# MMCSD8_MMC_CTLCFG_0FA00000h register map
Vendor: Texas Instruments
Registers are 16-bit, read-write, reset 0x0 unless marked. A register's access mark holds for its fields unless they carry their own. Offsets are as the file gives them; [hi:lo] are bit positions; lines under a group give offsets from that group.

## mmc_ctlcfg (part 4 of 4)
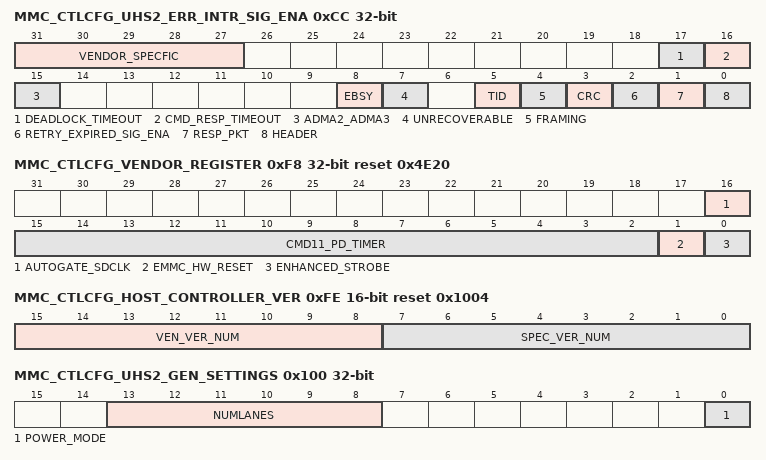
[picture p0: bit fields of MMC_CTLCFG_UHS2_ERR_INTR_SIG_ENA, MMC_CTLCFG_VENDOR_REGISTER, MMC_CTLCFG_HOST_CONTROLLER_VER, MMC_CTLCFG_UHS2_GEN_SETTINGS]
0xCC MMC_CTLCFG_UHS2_ERR_INTR_SIG_ENA 32-bit — This register is used to generate UHS-II Interrupt signals
  [31:27] VENDOR_SPECFIC — Setting of a bit to 1 in this field enables generating interrupt signal when corre-spondent bit of Vendor Specific Error is set in the UHS-II Error Interrupt Status Register. 0h - Interrupt Signal is Disabled 1h - Interrupt Signal is Enabled Reset Source: vbus_amod_g_rst_n
  [17] DEADLOCK_TIMEOUT — Setting this bit to 1 enables generating interrupt signal when Timeout for Dead lock bit is set in the UHS-II Error InterruptStatus Register. 0 Interrupt Signal is Disabled1 Interrupt Signal is Enabled
  [16] CMD_RESP_TIMEOUT — Setting this bit to 1 enables generating interrupt signal when Timeout for CMD_RES bit is set in the UHS-II Error InterruptStatus Register. 0 Interrupt Signal is Disabled1 Interrupt Signal is Enabled
  [15] ADMA2_ADMA3 — Setting this bit to 1 enables generating interrupt signal when ADMA2/3 Error bit is set in the UHS-II Error InterruptStatus Register. 0 Interrupt Signal is Disabled1 Interrupt Signal is Enabled
  [8] EBSY — Setting this bit to 1 enables generating interrupt signal when EBSY Error bit is set in the UHS-II Error InterruptStatus Register. 0 Interrupt Signal is Disabled1 Interrupt Signal is Enabled
  [7] UNRECOVERABLE — Setting this bit to 1 enables generating interrupt signal when Unrecoverable Error bit is set in the UHS-II Error InterruptStatus Register. 0 Interrupt Signal is Disabled1 Interrupt Signal is Enabled
  [5] TID — Setting this bit to 1 enables generating interrupt signal when TID Error bit is set in the UHS-II Error InterruptStatus Register. 0 Interrupt Signal is Disabled1 Interrupt Signal is Enabled
  [4] FRAMING — Setting this bit to 1 enables generating interrupt signal when Framing Error bit is set in the UHS-II Error InterruptStatus Register. 0 Interrupt Signal is Disabled1 Interrupt Signal is Enabled
  [3] CRC — Setting this bit to 1 enables generating interrupt signal when CRC Error bit is set in the UHS-II Error InterruptStatus Register. 0 Interrupt Signal is Disabled1 Interrupt Signal is Enabled
  [2] RETRY_EXPIRED_SIG_ENA — Setting this bit to 1 enables generating interrupt signal when Retry Expired bit is set in the UHS-II Error InterruptStatus Register. 0 Interrupt Signal is Disabled1 Interrupt Signal is Enabled
  [1] RESP_PKT — Setting this bit to 1 enables generating interrupt signal when RES Packet Error bit is set in the UHS-II Error InterruptStatus Register. 0 Interrupt Signal is Disabled1 Interrupt Signal is Enabled
  [0] HEADER — Setting this bit to 1 enables generating interrupt signal when Header Error bit is set in the UHS-II Error Interrupt Status Register. 0 Interrupt Signal is Disabled1 Interrupt Signal is Enabled
0xE0 MMC_CTLCFG_UHS2_SETTINGS_PTR ro reset 0x100 — This register is pointer for UHS-II settings.
  [15:0] UHS2_SETTINGS_PTR — Pointer for UHS-II Settings Register Reset Source: vbus_amod_g_rst_n
0xE2 MMC_CTLCFG_UHS2_CAPABILITIES_PTR ro reset 0x110 — This register is pointer for UHS-II Capabilities Register.
  [15:0] UHS2_CAPABILITIES_PTR — Pointer for UHS-II Capabilities Register Reset Source: vbus_amod_g_rst_n
0xE4 MMC_CTLCFG_UHS2_TEST_PTR ro reset 0x120 — This register is pointer for UHS-II Test Register.
  [15:0] UHS2_TEST_PTR — Pointer for UHS-II Test Register Reset Source: vbus_amod_g_rst_n
0xE6 MMC_CTLCFG_SHARED_BUS_CTRL_PTR ro reset 0x130 — This register is pointer for UHS-II Shared Bus Control Register.
  [15:0] SHARED_BUS_CTRL_PTR — Pointer for Shared Bus Control Register Reset Source: vbus_amod_g_rst_n
0xE8 MMC_CTLCFG_VENDOR_SPECFIC_PTR ro reset 0x140 — This register is pointer for UHS-II Vendor Specific Pointer Register.
  [15:0] VENDOR_SPECFIC_PTR — Pointer for Vendor Specific Area Reset Source: vbus_amod_g_rst_n
0xF4 MMC_CTLCFG_BOOT_TIMEOUT_CONTROL 32-bit — This is used to program the boot timeout value counter
  [31:0] DATA_TIMEOUT_CNT — This value determines the interval by which DAT line time-outs are detected during boot operation for eMMC4.4 card.The value is in number of sd clock. Reset Source: vbus_amod_g_rst_n
0xF8 MMC_CTLCFG_VENDOR_REGISTER 32-bit reset 0x4E20 — Vendor register added for autogate sdclk, cmd11 power down timer, enhancedstrobe and eMMC hardware reset
  [16] AUTOGATE_SDCLK — If this bit is set, SD CLK will be gated automatically when there is no transfer. This is applicable only for Embedded Device 0 Autogating of sdclk is Disabled1 Autogating of sdclk is Enabled
  [15:2] CMD11_PD_TIMER — cmd11 power-down timer value Reset Source: vbus_amod_g_rst_n
  [1] EMMC_HW_RESET — Hardware reset signal is generared for eMMC card when this bit is set 0 Deassert the hardware reset pin1 Drives the hardware reset pin as ZERO (Active LOW to eMMC card)
  [0] ENHANCED_STROBE — This bit enables the enhanced strobe logic of the Host Controller 0 Enhanced strobe is Disabled1 Enhanced strobe is Enabled
0xFC MMC_CTLCFG_SLOT_INT_STS ro — This register is used to read the interrupt signal for each slot.
  [7:0] INTR_SIG — These status bits indicate the logical OR of Interrupt signal and Wakeup signal for each slot. Reset Source: vbus_amod_g_rst_n
0xFE MMC_CTLCFG_HOST_CONTROLLER_VER ro reset 0x1004 — This register is used to read the vendor version number and specification version number
  [15:8] VEN_VER_NUM — The Vendor Version Number is set to 0x10 [1.0] Reset Source: vbus_amod_g_rst_n
  [7:0] SPEC_VER_NUM — This status indicates the Host Controller Spec. Version. The upper and lower 4-bits indicate the version. 00h - SD Host Controller Specification Version 1.00 01h - SD Host Controller Specification Version 2.00 Including the feature of the ADMA and Test Register 02h - SD Host Controller Specification Version 3.00 03h - SD Host Controller Specification Version 4.00 04h - SD Host Controller Specification Version 4.10 'others' Reserved 0 SD Host Controller Specifiation Version 1.001 SD Host Controller Specifiation Version 2.002 SD Host Controller Specifiation Version 3.003 SD Host Controller Specifiation Version 4.004 SD Host Controller Specifiation Version 4.10
0x100 MMC_CTLCFG_UHS2_GEN_SETTINGS 32-bit — Start Address of General settings is pointed by Pointer for UHS-II Setting Register.
  [13:8] NUMLANES — The lane configuration of a Host System is set to this field depends on the capability among Host Controller and connected devices. 2 Lanes FD mode is mandatory and the others modes are optional. 0000b - 2 Lanes FD or 2L-HD 0001b - Not Used 0010b - 3 Lanes 2D1U-FD [Embedded] 0011b - 3 Lanes 1D2U-FD [Embedded] 0100b - 4 Lanes 2D2U-FD [Embedded] others - Reserved Reset Source: vbus_amod_g_rst_n
  [0] POWER_MODE — This field determines either Fast mode or Low Power mode.Host and all devices connected to the host shall be set to the same mode. 0 Fast mode1 Low power mode
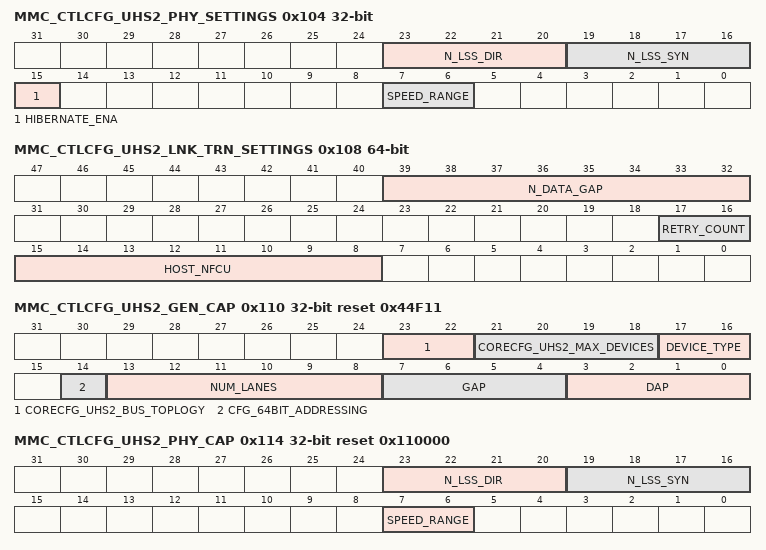
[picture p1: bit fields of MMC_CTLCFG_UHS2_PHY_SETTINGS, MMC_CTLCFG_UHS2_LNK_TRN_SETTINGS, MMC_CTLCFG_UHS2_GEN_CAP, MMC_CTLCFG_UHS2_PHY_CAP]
0x104 MMC_CTLCFG_UHS2_PHY_SETTINGS 32-bit — Start Address of PHY settings is pointed by Pointer for UHS-II Setting Register.
  [23:20] N_LSS_DIR — The largest value of N_LSS_DIR capabilities among the Host Controller and Connected Devices is set to this field. 0h - 8 x16 LSS 1h - 8 x 1 LSS 2h - 8 x 2 LSS 3h - 8 x 3 LSS ...... ...... Fh - 8 x 15 LSS Reset Source: vbus_amod_g_rst_n
  [19:16] N_LSS_SYN — The largest value of N_LSS_SYN capabilities among the Host Controller and Connected Devices is set to this field. 0h - 4 x16 LSS 1h - 4 x 1 LSS 2h - 4 x 2 LSS 3h - 4 x 3 LSS ...... ...... Fh - 4 x 15 LSS Reset Source: vbus_amod_g_rst_n
  [15] HIBERNATE_ENA — After checking card capability of Hibernate mode, if all devices support Hibernate mode, this bit may be set. This bit determines whether Host remains in Dormant state or goes to Hibernate state. In Hibernate mode, VDD1 Power may be off. 0 Hibernate Disabled1 Hibernate Enabled
  [7:6] SPEED_RANGE — PLL multiplier is selected by this field.Change of PLL Multiplier is not effective immediately and is applied from exiting Dormant State. '00' Range A [Default] '01' Range B '10' Reserved '11' Reserved 0 Range A (Default)1 Range B2 Reserved3 Reserved
0x108 MMC_CTLCFG_UHS2_LNK_TRN_SETTINGS 64-bit — Start Address of LINK/TRAN settings is pointed by Pointer for UHS-II Setting Register.
  [39:32] N_DATA_GAP — The largest value of N_DATA_GAP capabilities among the Host Controller and Connected Devices is set to this field. 00h - No Gap 01h - 1 LSS 02h - 2 LSS 03h - 3 LSS ...... ...... FFh - 255 LSS 0 No Gap1 1 LSS2 2 LSS3 3 LSS255 255 LSS
  [17:16] RETRY_COUNT — Data Burst retry count is set to this field. '00' Retry Disabled '01' 1 time '10' 2 times '11' 3 times 0 Retry Disabled1 Retry 1time2 Retry 2times3 Retry 3times
  [15:8] HOST_NFCU — Host Driver sets the number of blocks in Data Burst [Flow Control] to this field.The value shall be smaller than or equal to N_FCU capabilities among the Host Controller and connected card and devices. Setting 1 to 4 blocks is recommended considering buffer size. 00h - 256 Blocks 01h - 1 Block 02h - 2 Blocks 03h - 3 Blocks ...... ...... FFh - 255 Blocks 0 256 Blocks1 1 Block2 2 Blocks3 3 Blocks255 255 Blocks
0x110 MMC_CTLCFG_UHS2_GEN_CAP 32-bit ro reset 0x44F11 — Start Address of General Capabilities is pointed by Pointer for UHS-II Host Capabilities Register.
  [23:22] CORECFG_UHS2_BUS_TOPLOGY — This field indicates one of bus topologies configured by a Host system. '00' P2P Connection '01' Ring Connection '10' HUB Connection '11' HUB is connected in Ring 0 P2P Connection1 Ring Connection2 HUB Connection3 HUB is connected in Ring
  [21:18] CORECFG_UHS2_MAX_DEVICES — This field indicates the maximum number of devices supported by the Host Controller. 0h - Not used 1h - 1 Devices 2h - 2 Devices ..... ....... Fh - 15 Devices 0 Not used1 1 Device2 2 Devices15 15 Devices
  [17:16] DEVICE_TYPE — This field indicates device type configured by a Host system. '00' Removable Card[P2P] '01' Embedded Devices '10' Embedded Devices+Removable Card '11' Reserved Reset Source: vbus_amod_g_rst_n
  [14] CFG_64BIT_ADDRESSING — This field indicates support of 64-bit addressing by the Host Controller. '0' 32-bit Addressing is supported '1' 32-bit and 64-bit Addressing is supported Reset Source: vbus_amod_g_rst_n
  [13:8] NUM_LANES — This field indicates support of lanes by the Host Controller.0 mean not supported and 1 means supported. D08 - 2L-HD D09 - 2D1U-FD D10 - 1D2U-FD D11 - 2D2U-FD D12 - Reserved D13 - Reserved Reset Source: vbus_amod_g_rst_n
  [7:4] GAP — This field indicates the maximum capability of host power supply for a group configured by a Host system.This field is used to set the argument of DEVICE_INIT CCMD 0h -Not used 1h - 360 mW 2h - 720 mW ..... ....... Fh - 360x15 mW Reset Source: vbus_amod_g_rst_n
  [3:0] DAP — This field indicates the maximum capability of host power supply for a device configured by a Host system.This field is used to set the argument of DEVICE_INIT CCMD 0h -360 mW [Default] 1h - 360 mW 2h - 720 mW ..... ....... Fh - 360 x15 mW Reset Source: vbus_amod_g_rst_n
0x114 MMC_CTLCFG_UHS2_PHY_CAP 32-bit ro reset 0x110000 — Start Address of PHY Capabilities is pointed by Pointer for UHS-II Host Capabilities Register.
  [23:20] N_LSS_DIR — This field indicates the minimum N_LSS_DIR required by the Host Controller. 0h - 4 x16 LSS 1h - 4 x 1 LSS 2h - 4 x 2 LSS 3h - 4 x 3 LSS ...... ...... Fh - 4 x 15 LSS Reset Source: vbus_amod_g_rst_n
  [19:16] N_LSS_SYN — This field indicates the minimum N_LSS_SYN required by the Host Controller. 0h - 4 x16 LSS 1h - 4 x 1 LSS 2h - 4 x 2 LSS 3h - 4 x 3 LSS ...... ...... Fh - 4 x 15 LSS Reset Source: vbus_amod_g_rst_n
  [7:6] SPEED_RANGE — This field indicates supported Speed Range by the Host Controller '00' Range A [Default] '01' Range A and Range B '10' Reserved '11' Reserved 0 Range A (Default)1 Range A and Range B2 Reserved3 Reserved
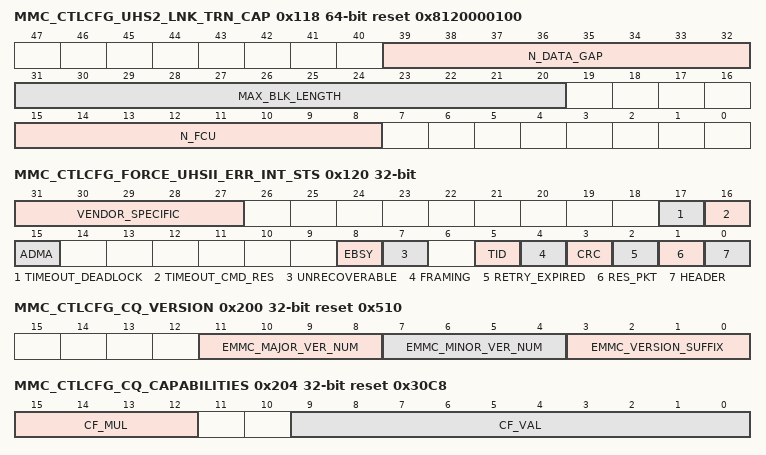
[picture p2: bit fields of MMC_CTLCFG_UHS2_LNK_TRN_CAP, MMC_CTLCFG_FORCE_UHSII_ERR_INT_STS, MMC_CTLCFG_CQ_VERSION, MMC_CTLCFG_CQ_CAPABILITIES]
0x118 MMC_CTLCFG_UHS2_LNK_TRN_CAP 64-bit ro reset 0x8120000100 — Start Address of LINK/TRAN settings is pointed by Pointer for UHS-II Capabilities Register.
  [39:32] N_DATA_GAP — This field indicates the minimum number of data gap[DIDL] supported by the Host Controller. 00h - No Gap 01h - 1 LSS 02h - 2 LSS 03h - 3 LSS ...... ...... FFh - 255 LSS 0 No Gap1 1 LSS2 2 LSS3 3 LSS255 255 LSS
  [31:20] MAX_BLK_LENGTH — This field indicates maximum block length by the Host Controller. 000h - Not Used 001h - 1 byte 002h - 2 bytes ...... ...... 200h - 512 bytes ...... ...... 800h - 2048 bytes 801h-FFFh -Not Used Reset Source: vbus_amod_g_rst_n
  [15:8] N_FCU — This field indicates maximum the number of blocks in a Flow Control unit by the Host Controller.This value is determined by supported buffer size. 00h - 256 Blocks 01h - 1 Block 02h - 2 Block 03h - 3 Block ....... FFh - 255 Blocks 0 256 Blocks1 1 Block2 2 Blocks3 3 Blocks255 255 Blocks
0x120 MMC_CTLCFG_FORCE_UHSII_ERR_INT_STS 32-bit wo — This register is not physically implemented, rather it is an address where UHS-II Error Interrupt Status register can be written.
  [31:27] VENDOR_SPECIFIC — Force Event for Vendor Specific Error 0h - Not Affected 1h - Vendor Specific Error Status is set Reset Source: vbus_amod_g_rst_n
  [17] TIMEOUT_DEADLOCK — Setting this bit forces the Host Controller to set Timeout for Deadlock in the UHS-II Error Interrupt Status register. 0 No Interrupt1 Timeout for Deadlock Error status is set
  [16] TIMEOUT_CMD_RES — Setting this bit forces the Host Controller to set Timeout for CMD_RES in the UHS-II Error Interrupt Status register. 0 No Interrupt1 Timout for CMD_RES Status is set
  [15] ADMA — Setting this bit forces the Host Controller to set ADMA Error in the UHS-II Error Interrupt Status register. 0 No Interrupt1 ADMA error status is set
  [8] EBSY — Setting this bit forces the Host Controller to set EBSY Error in the UHS-II Error Interrupt Status register. 0 No Interrupt1 EBSY error status is set
  [7] UNRECOVERABLE — Setting this bit forces the Host Controller to set Unrecover-able Error in the UHS-II Error Interrupt Status register. 0 No Interrupt1 Unrecoverable error status is set
  [5] TID — Setting this bit forces the Host Controller to set TID Error in the UHS-II Error Interrupt Status register. 0 No Interrupt1 TID error status is set
  [4] FRAMING — Setting this bit forces the Host Controller to set Framing Error in the UHS-II Error Interrupt Status register. 0 No Interrupt1 Framing error status is set
  [3] CRC — Setting this bit forces the Host Controller to set CRC Error in the UHS-II Error Interrupt Status register. 0 No Interrupt1 CRC error status is set
  [2] RETRY_EXPIRED — Setting this bit forces the Host Controller to set Retry Expired in the UHS-II Error Interrupt Status register. 0 No Interrupt1 Retry expired error status is set
  [1] RES_PKT — Setting this bit forces the Host Controller to set RES Packet Error in the UHS-II Error Interrupt Status register. 0 No Interrupt1 RES packet error status is set
  [0] HEADER — Setting this bit forces the Host Controller to set Header Error in the UHS-II Error Interrupt Status register. 0 No Interrupt1 Header error status is set
0x200 MMC_CTLCFG_CQ_VERSION 32-bit ro reset 0x510 — This register provides information about the version of the eMMC CQ standard which is 285 implemented by the CQE, in BCD format. The current version is rev 5.1 The following table describes the CQBASE+00h: CQVReservedER Command Queueing Version.
  [11:8] EMMC_MAJOR_VER_NUM — eMMC Major Version Number [digit left of decimal point],in BCD format Reset Source: vbus_amod_g_rst_n
  [7:4] EMMC_MINOR_VER_NUM — eMMC Minor Version Number [digit right of decimal point], in BCD format Reset Source: vbus_amod_g_rst_n
  [3:0] EMMC_VERSION_SUFFIX — eMMC Version Suffix [2nd digit right of decimal point], in BCD format Reset Source: vbus_amod_g_rst_n
0x204 MMC_CTLCFG_CQ_CAPABILITIES 32-bit ro reset 0x30C8 — This register is reserved for capability indication.
  [15:12] CF_MUL — Internal Timer Clock Frequency Multiplier [ITCFMUL] ITCFMUL and ITCFVAL indicate the frequency of the clock used for interrupt coalescing timer and for deter-mining the SQS polling period. See ITCFVAL definition for details. Field Value Description: 0h = 0.001 MHz 1h = 0.01 MHz 2h = 0.1 MHz 3h = 1 MHz 4h = 10 MHz Other values are reserved 3 1 MHz4 10 MHz
  [9:0] CF_VAL — Internal Timer Clock Frequency Value [ITCFVAL] TCFMUL and ITCFVAL indicate the frequency of the clock used for interrupt coalescing timer and for deter-mining the polling period when using periodic SEND_QUEUE_ STATUS [CMD13] polling. The clock frequency is calculated as ITCFVAL*ITCFMUL. For example, to encode 19.2 MHz ITCFVAL shall be C0h [= 192 decimal] and ITCFMUL shall be 2h [0.1 MHz 192 * 0.1 MHz 19.2 MHz] Reset Source: vbus_amod_g_rst_n
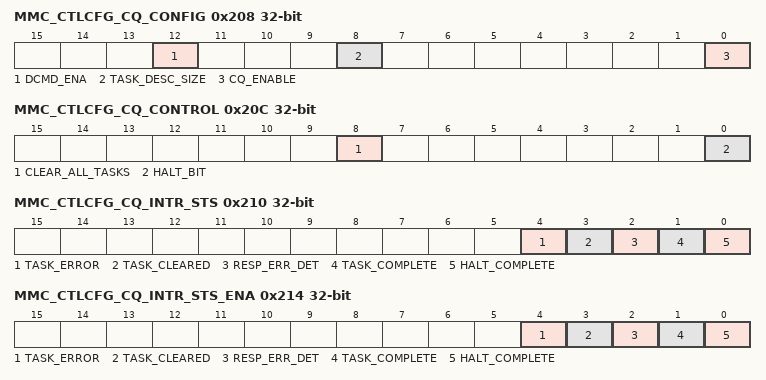
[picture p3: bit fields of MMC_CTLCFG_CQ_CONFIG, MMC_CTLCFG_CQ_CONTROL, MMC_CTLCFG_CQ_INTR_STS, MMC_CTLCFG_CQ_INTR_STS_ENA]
0x208 MMC_CTLCFG_CQ_CONFIG 32-bit — This register controls CQE behavior affecting the general operation of command queueing 290 module or operation of multiple tasks in the same time.
  [12] DCMD_ENA — Direct Command [DCMD] Enable This bit indicates to the hardware whether the Task Descriptor in slot #31 of the TDL is a Data Transfer Task Descriptor, or a Direct Command Task Descriptor. CQE uses this bit when a task is issued in slot #31, to determine how to decode the Task Descriptor. Bit Value Description 1 = Task descriptor in slot #31 is a DCMD Task Descrip-tor 0 = Task descriptor in slot #31 is a Data Transfer Task Descriptor 0 Task descriptor in slot #31 is a Data Transfer Task Descriptor1 Task descriptor in slot #31 is a DCMD Task Descriptor
  [8] TASK_DESC_SIZE — Task Descriptor Size This bit indicates whether the task descriptor size is 128 bits or 64 bits as detailed in Data Structures section. This bit can only be configured when Command Queueing Enable bit is 0 [command queueing is disabled] Bit Value Description 1 = Task descriptor size is 128 bits 0 = Task descriptor size is 64 bits 0 Task descriptor size is 64 bits1 Task descriptor size is 128 bits
  [0] CQ_ENABLE — Command Queueing Enable Software shall write 1 this bit when in order to enable command queueing mode [i.e. enable CQE]. When this bit is 0, CQE is disabled and software controls the eMMC bus using the legacy eMMC host controller. Before software writes 1 to this bit, software shall verify that the eMMC host controller is in idle state and there are no commands or data transfers ongoing. When software wants to exit command queueing mode,it shall clear all previous tasks if such exist before setting this bit to 0. 0 Command Queueing mode is Disabled1 Command Queueing mode is Enabled
0x20C MMC_CTLCFG_CQ_CONTROL 32-bit — This register controls CQE behavior affecting the general operation of command queueing 293 module or operation of multiple tasks in the same time.
  [8] CLEAR_ALL_TASKS — Clear All Tasks Software shall write 1 this bit when it wants to clear all the tasks sent to the device. This bit can only be written when CQE is in halt state [i.e.Halt bit is 1]. When software writes 1, the value of the register is updated to 1, and CQE shall reset CQTDBR register and all other context information for all unfinished tasks. Then CQE will clear this bit.Software should poll on this bit until it is set to back 0 and may then resume normal operation, by clearing the Halt bit. CQE does not communicate to the device that the tasks were cleared. It is softwares responsibility to order the device to discard the tasks in its queue using CMDQ_TASK_MGMT command. Writing 0 to this register shall have no effect. Reset Source: vbus_amod_g_rst_n
  [0] HALT_BIT — Halt Host software shall write 1 to the bit when it wants to acquire software control over the eMMC bus and disable CQE from issuing commands on the bus. For example, issuing a Discard Task command [CMDQ_TASK_MGMT] When software writes 1, CQE shall complete the ongo-ing task if such a task is in progress. Once the task is completed and CQE is in idle state,CQE shall not issue new commands and shall indicate so to software by setting this bit to 1. Software may poll on this bit until it is set to 1, and may only then send commands on the eMMC bus. In order to exit halt state [i.e. resume CQE activity], soft-ware shall clear this bit [write 0]. Writing 0 when thevalue is already 0 shall have no effect. Reset Source: vbus_amod_g_rst_n
0x210 MMC_CTLCFG_CQ_INTR_STS 32-bit access not given — This register indicates pending interrupts that require service. Each bit in this registers is asserted 296 in response a specific event, only if the respective bit is set in CQ ISTE register.
  [4] TASK_ERROR — Task Error Interrupt [TERR] This bit is asserted when task error is detected due to invalid task descriptor 0 No Interrupt1 Task Error interrupt is generated (access R/W1TC)
  [3] TASK_CLEARED — Task Cleared [TCL] This status bit is asserted [if CQISTE.TCL=1] when a task clear operation is completed by CQE. The com-pleted task clear operation is either an individual task clear [CQTCLR] or clearing of all tasks [CQCTL]. 0 No Interrupt1 Task clear interrupt is generated (access R/W1TC)
  [2] RESP_ERR_DET — Response Error Detected Interrupt [RED] This status bit is asserted [if CQISTE.RED=1] when a response is received with an error bit set in the device status field. The contents of the device status field are listed in Section 6.13.Software uses CQRMEM register to configure which device status bit fields may trigger an interrupt, and which are masked. Reset Source: vbus_amod_g_rst_n (access R/W1TC)
  [1] TASK_COMPLETE — Task Complete Interrupt [TCC] This status bit is asserted [if CQISTE.TCC=1] when atleast one of the following two conditions are met: [1] A task is completed and the INT bit is set in its Task Descriptor [2] Interrupt caused by Interrupt Coalescing logic [see Section C.4.9] 0 No Interrupt1 Task complete interrupt is generated (access R/W1TC)
  [0] HALT_COMPLETE — Halt Complete Interrupt [HAC] This status bit is asserted [if CQISTE.HAC=1] when halt bit in CQCTL register transitions from 0 to 1 indicating that host controller has completed its current ongoing task and has entered halt state. 0 No Interrupt1 Halt complete interrupt is generated (access R/W1TC)
0x214 MMC_CTLCFG_CQ_INTR_STS_ENA 32-bit — This register enables and disables the reporting of the corresponding interrupt to host soft-ware in 299 CQIS register. When a bit is set ( 1 ) and the corresponding interrupt c -ondition is active, then the 300 bit is CQIS is asserted. Interrupt sources that are disabled ( 0 ) are not indicated in the CQIS 301 register. This register is bit-index matched to CQIS register.
  [4] TASK_ERROR — Task Error Interrupt Status Enable 1 = CQIS.TERR will be set when its interrupt condition is active 0 = CQIS.TERR is disabled 01
  [3] TASK_CLEARED — Task Cleared Status Enable [TCL] 1 = CQIS.TCL will be set when its interrupt condition is active 0 = CQIS.TCL is disabled 01
  [2] RESP_ERR_DET — Response Error Detected Status Enable [RED] 1 = CQIS.RED will be set when its interrupt condition is active 0 = CQIS.RED is disabled 01
  [1] TASK_COMPLETE — Task Complete Status Enable [TCC] 1 = CQIS.TCC will be set when its interrupt condition is active 0 = CQIS.TCC is disabled 01
  [0] HALT_COMPLETE — Halt Complete Status Enable [HAC] 1 = CQIS.HAC will be set when its interrupt condition is active 0 = CQIS.HAC is disabled 01
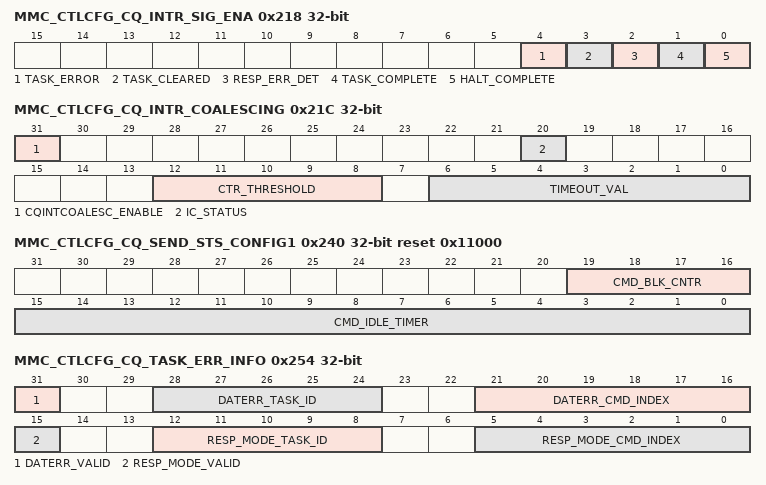
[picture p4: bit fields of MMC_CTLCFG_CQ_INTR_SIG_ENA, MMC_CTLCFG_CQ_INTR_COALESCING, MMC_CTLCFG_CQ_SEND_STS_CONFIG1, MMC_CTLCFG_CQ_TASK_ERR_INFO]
0x218 MMC_CTLCFG_CQ_INTR_SIG_ENA 32-bit — This register enables and disables the generation of interrupts to host software. When a bit is set 304 ( 1 ) and the corresponding bit in CQIS is set, then an interrupt is gene -rated. Interrupt sources 305 that are disabled ( 0 ) are still indicated in the CQIS register. This register is bit-index matched 306 to CQIS register.
  [4] TASK_ERROR — Task Error Interrupt Signal Enable [TERR] When set and CQIS.TERR is asserted, the CQE shall generate an interrupt 01
  [3] TASK_CLEARED — Task Cleared Signal Enable [TCL] When set and CQIS.TCL is asserted, the CQE shall generate an interrupt 01
  [2] RESP_ERR_DET — Response Error Detected Signal Enable [TCC] When set and CQIS.RED is asserted, the CQE shall generate an interrupt 01
  [1] TASK_COMPLETE — Task Complete Signal Enable [TCC] When set and CQIS.TCC is asserted, the CQE shall generate an interrupt 01
  [0] HALT_COMPLETE — Halt Complete Signal Enable [HAC] When set and CQIS.HAC is asserted, the CQE shall generate an interrupt 01
0x21C MMC_CTLCFG_CQ_INTR_COALESCING 32-bit access per field — This register controls the interrupt coalescing feature.
  [31] CQINTCOALESC_ENABLE rw — When set to 0 by software, command responses are neither counted nor timed. Interrupts are still triggered by completion of tasks with INT=1 in the Task Descriptor. When set to 1, the interrupt coalescing mechanism is enabled and coalesced interrupts are generated. Reset Source: vbus_amod_g_rst_n
  [20] IC_STATUS ro — This bit indicates to software whether any tasks [with INT=0] have completed and counted towards interrupt coalescing [i.e., ICSB is set if and only if IC counter > 0]. Bit Value Description 1 = At least one task completion has been counted [IC counter >0] 0 = No task completions have occurred since last counter reset [IC counter =0] Reset Source: vbus_amod_g_rst_n
  [12:8] CTR_THRESHOLD rw — Interrupt Coalescing Counter Threshold [ICCTH]: Software uses this field to configure the number of task completions [only tasks with INT=0 in the Task Descriptor] which are required in order to generate an interrupt. Counter Operation: As data transfer tasks with INT=0 complete, they are counted by CQE. The counter is reset by software during the interrupt service routine. The counter stops counting when it reaches the value configured in ICCTH. The maximum allowed value is 31 NOTE : When ICCTH is 0, task completions are not counted, and counting-based interrupts are not generated.In order to write to this field, the ICCTHWEN bit must be set at the same write operation. Reset Source: vbus_amod_g_rst_n
  [6:0] TIMEOUT_VAL rw — Interrupt Coalescing Timeout Value [ICTOVAL]: Software uses this field to configure the maximum time allowed between the completion of a task on the bus and the generation of an interrupt. Timer Operation: The timer is reset by software during the interrupt service routine. It starts running when a data transfer task with INT=0 is completed, after the timer was reset. When the timer reaches the value configured in ICTOVAL field it generates an interrupt and stops. The timers unit is equal to 1024 clock periods of the clock whose frequency is specified in the Internal Timer Clock Frequency field CQCAP register.The minimum value is 01h [1024 clock periods] and the maximum value is 7Fh [127*1024 clock periods]. For example, a CQCAP field value of 0 indicates a 19.2 MHz clock frequency [period = 52.08 ns]. If the setting in ICTOVAL is 10h, the calculated polling period is 16*1024*52.08 ns= 853.33 us NOTE: When ICTOVAL is 0, the timer is not running, and timer-based interrupts are not generated. In order to write to this field, the ICTOVALWEN bit must be set at the same write operation. Reset Source: vbus_amod_g_rst_n
0x220 MMC_CTLCFG_CQ_TDL_BASE_ADDR 32-bit — This register is used for configuring the lower 32 bits of the byte address of the head of the Task 312 Descriptor List in the host memory.
  [31:0] CQTDLBA_LO — Task Descriptor List Base Address [TDLBA] This register stores the LSB bits [bits 31:0] of the byte address of the head of the Task Descriptor List in system memory. The size of the task descriptor list is 32 * [Task Descrip-tor size + Transfer Descriptor size] as configured by Host driver. This address shall be set on Byte1 KByte boundary.: The lower 10 bits of this register shall be set to 0 by software and shall be ignored by CQE. Reset Source: vbus_amod_g_rst_n
0x224 MMC_CTLCFG_CQ_TDL_BASE_ADDR_UPBITS 32-bit — This register is used for configuring the upper 32 bits of the byte address of the head of the Task 316 Descriptor List in the host memory.
  [31:0] CQTDLBA_HI — Task Descriptor List Base Address [TDLBA] This register stores the MSB bits [bits 63:32] of the byte address of the head of the Task Descriptor List in system memory. The size of the task descriptor list is 32 * [Task Descrip-tor size + Transfer Descriptor size] as configured by Host driver. This register is reserved when using 32-bit addressing mode. Reset Source: vbus_amod_g_rst_n
0x228 MMC_CTLCFG_CQ_TASK_DOOR_BELL 32-bit access not given — Using this register, software triggers CQE to process a new task.
  [31:0] CQTDB_VAL — Command Queueing Task Doorbell Software shall configure TDLBA and TDLBAU, and enable CQE in CQCFG before using this register. Writing 1 to bit n of this register triggers CQE to start pro-cessing the task encoded in slot n of the TDL. CQE always processes tasks in-order according to the order submitted to the list by CQTDBR write transac-tions. CQE processes Data Transfer tasks by Reading the Task Descriptor and sending QUEUED_TASK_PARAMS[CMD44] and QUEUED_TASK_ADDRESS [CMD45]commands to the device. CQE processes DCMD tasks [in slot #31, when enabled]by Reading the Task Descriptor, and generating the com-mand encoded by its index and argument. The corresponding bit is cleared to 0 by CQE in one of the following events: [a] When a task execution is completed [with success or error] [b] The task is cleared using CQTCLR register [c] All tasks are cleared using CQCTL register [d] CQE is disabled using CQCFG register Software may initiate multiple tasks at the same time [batch submission] by Writing 1 to multiple bits of this register in the same transaction. In the case of batch submission: CQE shall process the tasks in order of the task index,starting with the lowest index. If one or more tasks in the batch are marked with QBR,the ordering of execution will be based on said process-ing order. Writing 0 by software shall have no impact on the hard-ware, and will not change the value of the register bit. Reset Source: vbus_amod_g_rst_n (access R/W1TS)
0x22C MMC_CTLCFG_CQ_TASK_COMP_NOTIF 32-bit access not given — This register is used by CQE to notify software about completed tasks.
  [31:0] CQTCN_VAL — CQE shall set bit n of this register [at the same time it clears bit n of CQTDBR] when a task execution is com-pleted [with success or error].When receiving interrupt for task completion, software may read this register to know which tasks have finished. After Reading this register, software may clear the rele-vant bit fields by Writing 1 to the corresponding bits. Reset Source: vbus_amod_g_rst_n (access R/W1TC)
0x230 MMC_CTLCFG_CQ_DEV_QUEUE_STATUS 32-bit ro — This register stores the most recent value of the device s queue status.
  [31:0] CQDQ_STS — Every time the Host controller receives a queue status register [QSR] from the device, it updates this register with the response of status command, i.e. the devicesqueue status. Reset Source: vbus_amod_g_rst_n
0x234 MMC_CTLCFG_CQ_DEV_PENDING_TASKS 32-bit ro — This register indicates to software which tasks are queued in the device, awaiting execution.
  [31:0] CQDP_TSKS — Bit n of this register is set if and only if QUEUED_TASK_PARAMS [CMD44] and QUEUED_TASK_ADDRESS [CMD45] were sent for this specific task and if this task hasnt been executed yet.CQE shall set this bit after receiving a successful response for CMD45. CQE shall clear this bit after the task has completed execution.Software needs to read this register in the task-discard procedure, when the controller is halted, to determine if the task is queued in the device. If the task is queued,the driver sends a CMDQ_TASK_MGMT [CMD48] to the device ordering it to discard the task. Then software clears the task in the CQE. Only then the software orders CQE to resume its operation using CQCTL register. Reset Source: vbus_amod_g_rst_n
0x238 MMC_CTLCFG_CQ_TASK_CLEAR 32-bit — This register is used for removing an outstanding task in the CQE. 327. The register should be used only when CQE is in Halt state.
  [31:0] CQTCLR — Writing 1 to bit n of this register orders CQE to clear a task which software has previously issued.This bit can only be written when CQE is in Halt state as indicated in CQCFG register Halt bit.When software writes 1 to a bit in this register,CQE updates the value to 1, and starts clearing the data structures related to the task. CQE clears the bit fields [sets a value of 0] in CQTCLR and in CQTDBR once clear operation is complete.Software should poll on the CQTCLR until it is cleared to verify clear operation was complete.Writing to this register only clears the task in the CQEand does not have impact on the device. In order to dis-card the task in the device, host software shall send CMDQ_TASK _MGMT while CQE is still in Halt state.Host driver is not allowed to use this register to clearmultiple tasks at the same time. Clearing multiple tasks can be done using CQCTL register.Writing 0 to a register bit shall have no impact. Reset Source: vbus_amod_g_rst_n
0x240 MMC_CTLCFG_CQ_SEND_STS_CONFIG1 32-bit reset 0x11000 — The register controls the when SEND_QUEUE_STATUS commands are sent.
  [19:16] CMD_BLK_CNTR — This field indicates to CQE when to send SEND_QUEUE_STATUS [CMD13] command to inquire the status of the devices task queue.A value of n means CQE shall send status command on the CMD line, during the transfer of data block BLOCK_CNT-n, on the data lines, where BLOCK_CNT is the number of blocks in the current transaction.A value of 0 means that SEND_QUEUE_STATUS [CMD13] command shall not be sent during the transac-tion. Instead it will be sent only when the data lines are idle.A value of 1 means that STATUS command is to be sent during the last block of the transaction. Reset Source: vbus_amod_g_rst_n
  [15:0] CMD_IDLE_TIMER — This field indicates to CQE the polling period to use when using periodic SEND_QUEUE_STATUS [CMD13] polling.Periodic polling is used when tasks are pending in thedevice, but no data transfer is in progress. When a SEND_QUEUE_STATUS response indicating that no task is ready for execution, CQE counts the configured time until it issues the next SEND_QUEUE_STATUS.Timer units are clock periods of theclock whose fre-quency is specified in the Internal Timer Clock Fre-quency field CQCAP register.The minimum value is 0001h [1 clock period] and the maximum value is FFFFh [65535 clock periods]. Default interval is: 4096 clock periods.For example, a CQCAP field value of 0 indicates a 19.2 MHz clock frequency [period = 52.08 ns]. If the setting in CQSST is 1000h, the calcu.lated polling period is 4096*52.08 ns= 213.33 us. Reset Source: vbus_amod_g_rst_n
0x244 MMC_CTLCFG_CQ_SEND_STS_CONFIG2 32-bit — This register is used for 333 configuring RCA field in SEND_QUEUE_STATUS command argu-ment.
  [15:0] QUEUE_RCA — This field provides CQE with the contents of the 16-bit RCA field in SEND_QUEUE_ STATUS [CMD13] com-mand. argument.CQE shall copy this field to bits 31:16 of the argument when transmitting SEND_ QUEUE_STATUS [CMD13] command. Reset Source: vbus_amod_g_rst_n
0x248 MMC_CTLCFG_CQ_DCMD_RESPONSE 32-bit ro — This register is used for passing the response of a DCMD task to software.
  [31:0] LAST_RESP — This register contains the response of the command generated by the last direct-command [DCMD] task which was sent.CQE shall update this register when it receives theresponse for a DCMD task. This register is considered valid only after bit 31 of CQT-DBR register is cleared by CQE. Reset Source: vbus_amod_g_rst_n
0x250 MMC_CTLCFG_CQ_RESP_ERR_MASK 32-bit reset 0xFDF9A080 — This register controls the generation of Response Error Detection (RED) interrupt.
  [31:0] CQRMEM — This bit is used as in interrupt mask on the device status filed which is received in R1/R1b responses.Bit Value Description [for any bit i]:1 = When a R1/R1b response is received, with bit i in the device status set, a RED interrupt is generated 0 = When a R1/R1b response is received, bit i in the device status is ignored The reset value of this register is set to trigger an inter-rupt on all Error type bits in the device status, as defined in Section 6.13.NOTE: Responses to CMD13 [SQS] encode the QSR,so they are ignored by this logic Reset Source: vbus_amod_g_rst_n
0x254 MMC_CTLCFG_CQ_TASK_ERR_INFO 32-bit ro — This register is updated by CQE when an error occurs on data or command related to a task activity. When such error is detected by CQE or indicated by the eMMC controller CQE stores in CQTERRI the task IDs and the command indices of the commands which were executed on the 343 command line and data lines when the error occurred.Software is expected to use this information in the error recovery procedure.
  [31] DATERR_VALID — Data Transfer Error Fields Valid This bit is updated when an error is detected by CQE, or indicated by eMMC controller. If a data transfer is in progress when the error is detected/indicated, the bit is set to 1. If a no data transfer is in progress when the error is detected/indicated, the bit is cleared to 0. Reset Source: vbus_amod_g_rst_n
  [28:24] DATERR_TASK_ID — Data Transfer Error Task ID This field indicates the ID of the task which was executed on the data lines when an error occurred. The field is updated if a data transfer is in progress when an error is detected by CQE, or indicated by eMMC controller Reset Source: vbus_amod_g_rst_n
  [21:16] DATERR_CMD_INDEX — Data Transfer Error Command Index This field indicates the index of the command which was executed on the data lines when an error occurred. The index shall be set to EXECUTE_READ_TASK[CMD46] or EXECUTE_WRITE_TASK [CMD47] accord-ing to the data direction. The field is updated if a data transfer is in progress when an error is detected by CQE, or indicated by eMMC controller. Reset Source: vbus_amod_g_rst_n
  [15] RESP_MODE_VALID — Response Mode Error Fields Valid This bit is updated when an error is detected by CQE, or indicated by eMMC controller. If a command transaction is in progress when the error is detected/indicated, the bit is set to 1. If a no command transaction is in progress when the error is detected/indicated, the bit is cleared to 0. Reset Source: vbus_amod_g_rst_n
  [12:8] RESP_MODE_TASK_ID — Response Mode Error Task ID This field indicates the ID of the task which was executed on the command line when an error occurred. The field is updated if a command transaction is in progress when an error is detected by CQE, or indicated by eMMC controller. Reset Source: vbus_amod_g_rst_n
  [5:0] RESP_MODE_CMD_INDEX — Response Mode Error Command Index This field indicates the index of the command which was executed on the command line when an error occurred. The field is updated if a command transaction is in progress when an error is detected by CQE, or indicated by eMMC controller. Reset Source: vbus_amod_g_rst_n
0x258 MMC_CTLCFG_CQ_CMD_RESP_INDEX 32-bit ro — This register stores the index of the last received command response.
  [5:0] LAST_CRI — This field stores the index of the last received command response. CQE shall update the value every time a com-mand response is received. Reset Source: vbus_amod_g_rst_n
0x25C MMC_CTLCFG_CQ_CMD_RESP_ARG 32-bit ro — This register stores the index of the last received command response.
  [31:0] LAST_CRA — This field stores the argument of the last received com-mand. CQE shall update the value every time a com-mand response is received. Reset Source: vbus_amod_g_rst_n
0x260 MMC_CTLCFG_CQ_ERROR_TASK_ID 32-bit ro — CQ Error Task ID Register
  [4:0] TERR_ID — Task Error ID Reset Source: vbus_amod_g_rst_n
